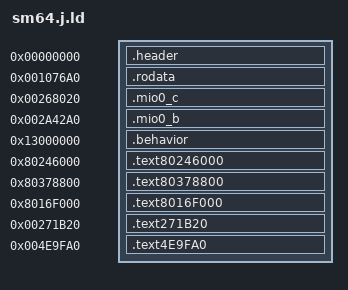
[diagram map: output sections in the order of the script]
/* Super Mario 64 (J) linker script
 * generated by n64split v0.4a - N64 ROM splitter */

OUTPUT_ARCH (mips)

SECTIONS
{
   /* header and boot */
   .header 0x0 : AT(0x0) {
      * (.header);
      * (.boot);
   }

   /* load MIO0 and level data at 0x801076A0 */
   .rodata 0x001076A0 : AT(0x1076A0) {
      FILL (0x01) /* fill unused with 0x01 */
      * (.mio0);
      * (.data);
      . = ALIGN(0x10);
   }

   /* 0x268020 0x268020-0 [0] */
   .mio0_c 0x268020 : AT(0x268020) {
      * (.mio0_c);
   }

   /* 0x2A42A0 0x2A42A0-0 [0] */
   .mio0_b 0x2A42A0 : AT(0x2A42A0) {
      * (.mio0_b);
   }

   /* use segmented addressing for behaviors */
   .behavior 0x13000000 : AT(0x218130) {
      FILL (0x01) /* fill unused with 0x01 */
      * (.behavior);
      behavior_length = . - 0x13000000;
   }
   __load_behavior_data = LOADADDR(.behavior);
   __load_behavior_data_end = LOADADDR(.behavior) + behavior_length;

   /* 0x80246000 001000-0E5320 [E4320] */
   .text80246000 0x80246000 : AT(0x001000) {
      * (.text80246000);
   }

   /* 0x80378800 0F4210-101998 [D788] */
   .text80378800 0x80378800 : AT(0x0F4210) {
      * (.text80378800);
   }

   /* 0x8016F000 21D7D0-255EC0 [386F0] */
   .text8016F000 0x8016F000 : AT(0x21D7D0) {
      * (.text8016F000);
   }

   /* 271B20-2A42A0 [32780] */
   .text271B20 0x271B20 : AT(0x271B20) {
      * (.text271B20);
   }

   /* 4E9FA0-0 [0] */
   .text4E9FA0 0x4E9FA0 : AT(0x4E9FA0) {
      * (.text4E9FA0);
   }

   /* Discard everything not specifically mentioned above. */
   /DISCARD/ :
   {
      *(*);
   }
}
